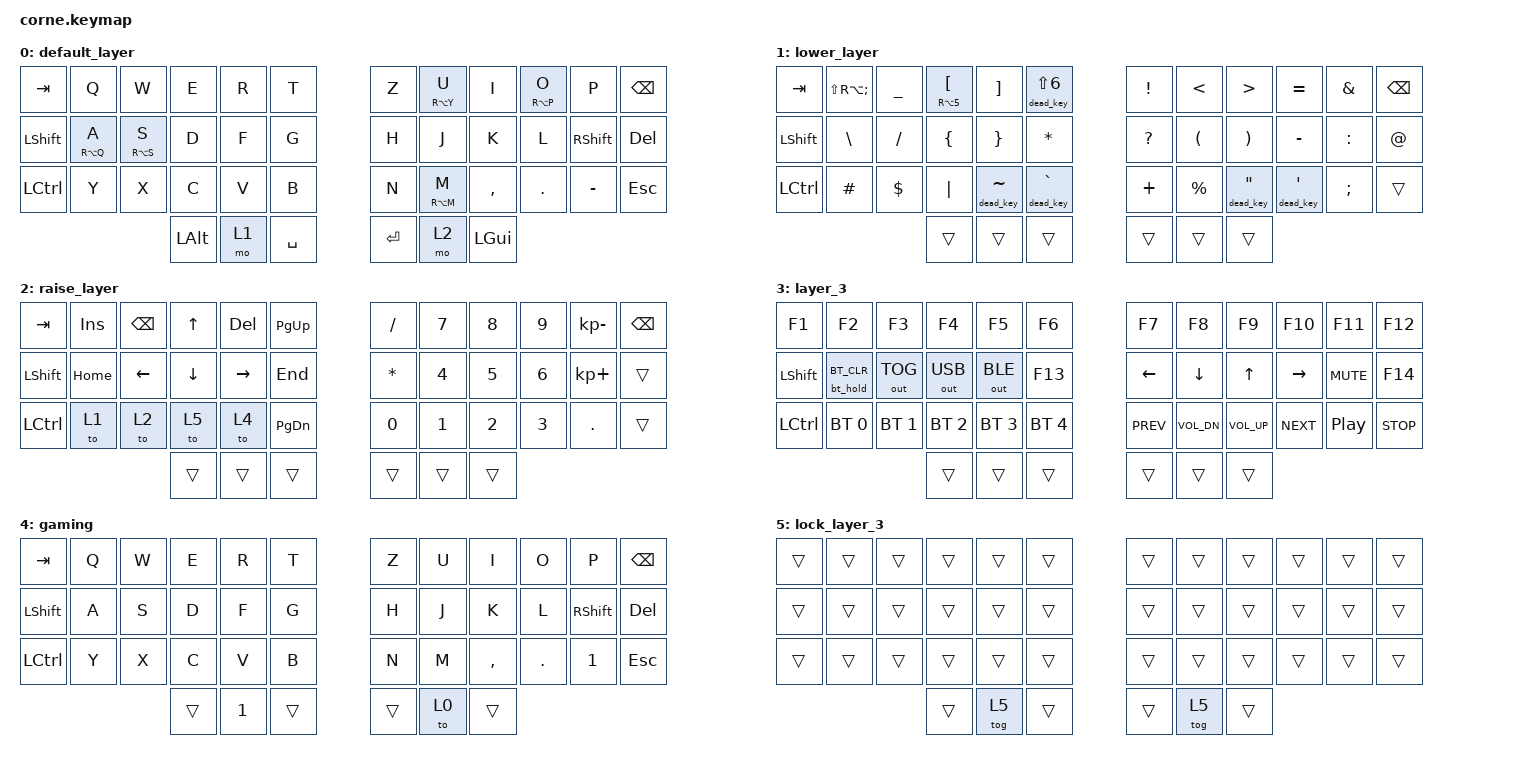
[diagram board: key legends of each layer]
/*
 * Copyright (c) 2020 The ZMK Contributors
 *
 * SPDX-License-Identifier: MIT
 */
// https://nickcoutsos.github.io/keymap-editor/

#include <behaviors.dtsi>
#include <dt-bindings/zmk/bt.h>
#include <dt-bindings/zmk/keys.h>
#include <dt-bindings/zmk/outputs.h>

/ {
    behaviors {
        umlaut_hold: umlaut_hold {
            compatible = "zmk,behavior-hold-tap";
            bindings = <&kp>, <&kp>;

            #binding-cells = <2>;
            tapping-term-ms = <200>;
            flavor = "tap-preferred";
        };

        layer_tap_lock: layer_tap_lock {
            compatible = "zmk,behavior-hold-tap";
            bindings = <&mo>, <&tog>;

            #binding-cells = <2>;
            tapping-term-ms = <100>;
        };

        bt_hold: bt_hold {
            compatible = "zmk,behavior-hold-tap";
            bindings = <&bt>, <&none>;

            #binding-cells = <2>;
            tapping-term-ms = <2000>;
            flavor = "tap-preferred";
        };
    };

    macros {
        dead_key: dead_key {
            compatible = "zmk,behavior-macro-one-param";
            #binding-cells = <1>;
            bindings = <&macro_param_1to1 &kp MACRO_PLACEHOLDER &kp SPACE>;
            label = "DEAD_KEY";
        };
    };

    keymap {
        compatible = "zmk,keymap";

        default_layer {
            // -----------------------------------------------------------------------------------------
            // |  TAB |  Q  |  W  |  E  |  R  |  T  |   |  Z  |  U   |  I  |  O  |  P  | BKSP |
            // | SHFT |  A  |  S  |  D  |  F  |  G  |   |  H  |  J   |  K  |  L  |     | DEL  |
            // | CTRL |  Y  |  X  |  C  |  V  |  B  |   |  N  |  M   |  ,  |  .  |  -  | ESC  |
            //                    | ALT | LWR | SPC |   | ENT | RSE  | GUI |

            bindings = <
&kp TAB         &kp Q                 &kp W                 &kp E     &kp R  &kp T        &kp Z    &umlaut_hold RA(Y) U  &kp I      &umlaut_hold RA(P) O  &kp P       &kp BSPC
&kp LEFT_SHIFT  &umlaut_hold RA(Q) A  &umlaut_hold RA(S) S  &kp D     &kp F  &kp G        &kp H    &kp J                 &kp K      &kp L                 &kp RSHIFT  &kp DELETE
&kp LCTRL       &kp Y                 &kp X                 &kp C     &kp V  &kp B        &kp N    &umlaut_hold RA(M) M  &kp COMMA  &kp DOT               &kp MINUS   &kp ESC
                                                            &kp LALT  &mo 1  &kp SPACE    &kp RET  &mo 2                 &kp LGUI
            >;
        };

        lower_layer {
            // -----------------------------------------------------------------------------------------
            // |  TAB |  °  |  _  |  [  |  ]  |  ^  |   |  !  |  <  |  >  |  =  |  &  | BKSP |
            // | SHFT |  \  |  /  |  {  |  }  |  *  |   |  ?  |  (  |  )  |  -  |  :  |  @   |
            // | CTRL |  #  |  $  |  |  |  ~  |  `  |   |  +  |  %  |  "  |  '  |  ;  |      |
            //                    | ALT | LWR | SPC |   | ENT | RSE  | GUI |

            bindings = <
&kp TAB    &kp LS(RA(SEMICOLON))  &kp UNDER   &umlaut_hold RA(N5) LEFT_BRACKET  &kp RIGHT_BRACKET  &dead_key LS(N6)    &kp EXCLAMATION  &kp LESS_THAN         &kp GREATER_THAN         &kp EQUAL      &kp AMPERSAND  &kp BSPC
&kp LSHFT  &kp BACKSLASH          &kp SLASH   &kp LEFT_BRACE                    &kp RIGHT_BRACE    &kp ASTERISK        &kp QUESTION     &kp LEFT_PARENTHESIS  &kp RIGHT_PARENTHESIS    &kp MINUS      &kp COLON      &kp AT_SIGN
&kp LCTRL  &kp HASH               &kp DOLLAR  &kp PIPE                          &dead_key TILDE    &dead_key GRAVE     &kp PLUS         &kp PERCENT           &dead_key DOUBLE_QUOTES  &dead_key SQT  &kp SEMICOLON  &trans
                                              &trans                            &trans             &trans              &trans           &trans                &trans
            >;
        };

        raise_layer {
            // -----------------------------------------------------------------------------------------
            // |  TAB | INS | BKSP|  UP | DEL |PG_UP|   |  /  |  7  |  8  |  9  |  -  | BKSP |
            // | SHFT |HOME | LEFT|DOWN |RIGHT| END |   |  *  |  4  |  5  |  6  |  +  |      |
            // | CTRL |     |     |     |     |PG_DW|   |  0  |  1  |  2  |  3  |  .  |      |
            //                    | ALT | LWR | SPC |   | ENT | RSE  | GUI |

            bindings = <
&kp TAB    &kp INS   &kp BSPC  &kp UP    &kp DEL    &kp PG_UP    &kp FSLH  &kp N7  &kp N8  &kp N9  &kp KP_SUBTRACT  &kp BSPC
&kp LSHFT  &kp HOME  &kp LEFT  &kp DOWN  &kp RIGHT  &kp END      &kp STAR  &kp N4  &kp N5  &kp N6  &kp KP_PLUS      &trans
&kp LCTRL  &to 1     &to 2     &to 5     &to 4      &kp PG_DN    &kp N0    &kp N1  &kp N2  &kp N3  &kp DOT          &trans
                               &trans    &trans     &trans       &trans    &trans  &trans
            >;
        };

        // -----------------------------------------------------------------------------------------
        // |  F1  | F2   | F3    | F4  | F5  | F6  |   | F7  | F8  | F9  | F10 | F11  | F12 |
        // | SHFT |BT_CLR|OUT_TOG|USB  | BLE | F13 |   |LEFT |DOWN | UP  |RIGHT|MUTE  | F14 |
        // | CTRL | BR_0 | BR_1  | BR_2| BR_3| BT_4|   |PREV |VL_DW|VL_UP|NEXT |Pl/Pau|STOP |
        //                       | ALT | LWR | SPC |   | ENT | RSE  | GUI |

        layer_3 {
            bindings = <
&kp F1     &kp F2           &kp F3        &kp F4        &kp F5        &kp F6          &kp F7      &kp F8        &kp F9        &kp F10     &kp F11           &kp F12
&kp LSHFT  &bt_hold BT_CLR  &out OUT_TOG  &out OUT_USB  &out OUT_BLE  &kp F13         &kp LEFT    &kp DOWN      &kp UP        &kp RIGHT   &kp C_MUTE        &kp F14
&kp LCTRL  &bt BT_SEL 0     &bt BT_SEL 1  &bt BT_SEL 2  &bt BT_SEL 3  &bt BT_SEL 4    &kp C_PREV  &kp C_VOL_DN  &kp C_VOL_UP  &kp C_NEXT  &kp C_PLAY_PAUSE  &kp C_STOP
                                          &trans        &trans        &trans          &trans      &trans        &trans
            >;
        };

        // -----------------------------------------------------------------------------------------
        // |  TAB |  Q  |  W  |  E  |  R  |  T  |   |  Z  |  U   |  I  |  O  |  P  | BKSP |
        // | SHFT |  A  |  S  |  D  |  F  |  G  |   |  H  |  J   |  K  |  L  |     | DEL  |
        // | CTRL |  Y  |  X  |  C  |  V  |  B  |   |  N  |  M   |  ,  |  .  |  -  | ESC  |
        //                    | ALT | LWR | SPC |   | ENT | RSE  | GUI |

        gaming {
            bindings = <
&kp TAB         &kp Q  &kp W  &kp E   &kp R   &kp T     &kp Z   &kp U  &kp I      &kp O    &kp P         &kp BSPC
&kp LEFT_SHIFT  &kp A  &kp S  &kp D   &kp F   &kp G     &kp H   &kp J  &kp K      &kp L    &kp RSHIFT    &kp DELETE
&kp LCTRL       &kp Y  &kp X  &kp C   &kp V   &kp B     &kp N   &kp M  &kp COMMA  &kp DOT  &kp NUMBER_1  &kp ESC
                              &trans  &kp N1  &trans    &trans  &to 0  &trans
            >;
        };

        lock_layer_3 {
            bindings = <
&trans  &trans  &trans  &trans  &trans  &trans    &trans  &trans  &trans  &trans  &trans  &trans
&trans  &trans  &trans  &trans  &trans  &trans    &trans  &trans  &trans  &trans  &trans  &trans
&trans  &trans  &trans  &trans  &trans  &trans    &trans  &trans  &trans  &trans  &trans  &trans
                        &trans  &tog 5  &trans    &trans  &tog 5  &trans
            >;
        };
    };

    conditional_layers {
        compatible = "zmk,conditional-layers";

        layer_3 {
            if-layers = <1 2>;
            then-layer = <3>;
        };

        layer_3_lock {
            if-layers = <5>;
            then-layer = <3>;
        };
    };
};
